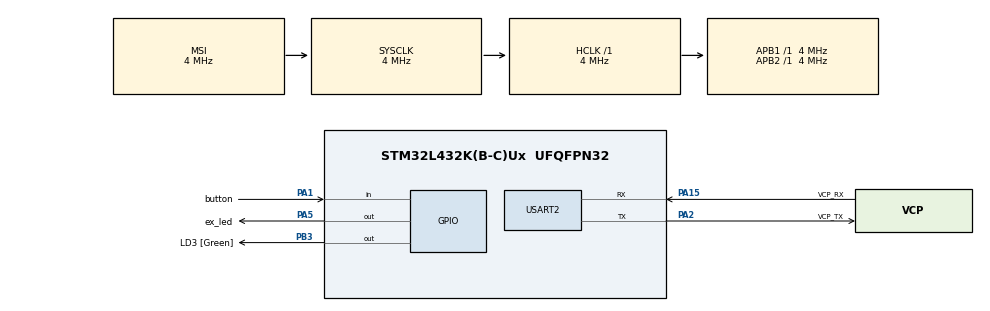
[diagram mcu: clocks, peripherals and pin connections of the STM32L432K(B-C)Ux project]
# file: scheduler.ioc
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Mcu.Family=STM32L4
Mcu.Name=STM32L432K(B-C)Ux
Mcu.Package=UFQFPN32
NVIC.PriorityGroup=NVIC_PRIORITYGROUP_4
NVIC.TIM1_UP_TIM16_IRQn=true\:0\:0\:false\:false\:true\:true\:true\:true
PA0.GPIO_Label=MCO [High speed clock in]
PA0.Mode=HSE-External-Clock-Source-for-LittleOrca
PA0.Signal=RCC_CK_IN
PA1.GPIO_Label=button
PA1.GPIO_PuPd=GPIO_PULLUP
PA1.Signal=GPIO_Input
PA13\ (JTMS-SWDIO).GPIO_Label=SWDIO
PA13\ (JTMS-SWDIO).Mode=Serial_Wire
PA13\ (JTMS-SWDIO).Signal=SYS_JTMS-SWDIO
PA14\ (JTCK-SWCLK).GPIO_Label=SWCLK
PA14\ (JTCK-SWCLK).Mode=Serial_Wire
PA14\ (JTCK-SWCLK).Signal=SYS_JTCK-SWCLK
PA15\ (JTDI).GPIO_Label=VCP_RX
PA15\ (JTDI).Mode=Asynchronous
PA15\ (JTDI).Signal=USART2_RX
PA2.GPIO_Label=VCP_TX
PA2.Mode=Asynchronous
PA2.Signal=USART2_TX
PA5.GPIO_Label=ex_led
PA5.Signal=GPIO_Output
PB3\ (JTDO-TRACESWO).GPIO_Label=LD3 [Green]
PB3\ (JTDO-TRACESWO).Signal=GPIO_Output
PC14-OSC32_IN\ (PC14).Mode=LSE-External-Oscillator
PC14-OSC32_IN\ (PC14).Signal=RCC_OSC32_IN
PC15-OSC32_OUT\ (PC15).Mode=LSE-External-Oscillator
PC15-OSC32_OUT\ (PC15).Signal=RCC_OSC32_OUT
ProjectManager.HeapSize=0x200
ProjectManager.StackSize=0x400
ProjectManager.TargetToolchain=STM32CubeIDE
RCC.AHBFreq_Value=4000000
RCC.APB1Freq_Value=4000000
RCC.APB1TimFreq_Value=4000000
RCC.APB2Freq_Value=4000000
RCC.APB2TimFreq_Value=4000000
RCC.CortexFreq_Value=4000000
RCC.HCLKFreq_Value=4000000
RCC.HSE_VALUE=8000000
RCC.HSI16_VALUE=16000000
RCC.HSI48_VALUE=48000000
RCC.HSI_VALUE=16000000
RCC.MSI_VALUE=4000000
RCC.PLLMUL=RCC_PLLMUL_4
RCC.PLLN=16
RCC.SYSCLKFreq_VALUE=4000000
RCC.VCOOutputFreq_Value=64000000
TIM1.Period=3
TIM1.Prescaler=999
USART2.VirtualMode-Asynchronous=VM_ASYNC
VP_TIM1_VS_ClockSourceINT.Mode=Internal
board=NUCLEO-L432KC

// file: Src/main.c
#include "main.h"
#include <string.h>
#include <stdarg.h>
#include <stdio.h>
#include <stdint.h>

void Button_Task(void);
extern UART_HandleTypeDef huart2;
volatile uint32_t msTicks = 0;

void UART_Print(const char *msg)
{
    HAL_UART_Transmit(&huart2, (uint8_t*)msg, strlen(msg), HAL_MAX_DELAY);
}

void UART_Printf(const char *fmt, ...)
{
    char buf[128];
    va_list args;
    va_start(args, fmt);
    vsnprintf(buf, sizeof(buf), fmt, args);
    va_end(args);
    HAL_UART_Transmit(&huart2, (uint8_t*)buf, strlen(buf), HAL_MAX_DELAY);
}

TIM_HandleTypeDef htim1;

UART_HandleTypeDef huart2;

/* USER CODE BEGIN PV */
uint16_t data[]={GPIO_PIN_5,0x0000};
static uint32_t lastL  = 0;
static uint32_t lastU = 0;
static uint32_t lastB = 0;

/* USER CODE END PV */

void SystemClock_Config(void);
static void MX_GPIO_Init(void);
static void MX_TIM1_Init(void);
static void MX_USART2_UART_Init(void);

/* USER CODE BEGIN 0 */
void HAL_TIM_PeriodElapsedCallback(TIM_HandleTypeDef *htim) {
    if (htim->Instance == TIM1) {  // or TIM1, TIM6, etc.
        msTicks++;  // count milliseconds
    }
}
/* USER CODE END 0 */

int main(void)
{

  /* MCU Configuration--------------------------------------------------------*/

  /* Reset of all peripherals, Initializes the Flash interface and the Systick. */
  HAL_Init();

  /* Configure the system clock */
  SystemClock_Config();

  /* Initialize all configured peripherals */
  MX_GPIO_Init();
  MX_TIM1_Init();
  MX_USART2_UART_Init();
  /* USER CODE BEGIN 2 */
   //__HAL_TIM_ENABLE_DMA(&htim1, TIM_DMA_UPDATE);
   //HAL_DMA_Start(&hdma_tim1_up,(uint32_t)data,(uint32_t)&GPIOA->ODR,2);
   HAL_TIM_Base_Start_IT(&htim1);
  /* USER CODE BEGIN 2 */

  /* USER CODE END 2 */

  /* Infinite loop */
  /* USER CODE BEGIN WHILE */
   while (1) {
       uint32_t now = msTicks;
       uint32_t ms = msTicks;             // snapshot
       uint32_t s  = ms / 1000;
       uint32_t ms_rem = ms % 1000;
       static uint32_t c = 0;
       static uint8_t led_on = 0;
       if ((now - lastL) >= 1500) {
    	   lastL = now;
    	   if (!led_on) {
    	           HAL_GPIO_WritePin(ex_led_GPIO_Port, ex_led_Pin, GPIO_PIN_SET);
    	           led_on = 1;
    	           c++;                // count only when turning on
    	       } else {
    	           HAL_GPIO_WritePin(ex_led_GPIO_Port, ex_led_Pin, GPIO_PIN_RESET);
    	           led_on = 0;
    	       }
       }
       if ((now - lastU) >= 3000) {
           UART_Printf("Total time elapsed in milliseconds: %lu milliseconds\r\n", msTicks);
           for(int i = 0; i < 1000; i++){
        	   int j = i/1000;
           }
           UART_Printf("Total time elapsed in: %lu.%09lu seconds\r\n", s, ms_rem);
          // UART_Printf("LED has flashed %lu times \r\n", c);
           lastU = now;
       }
       if ((now - lastB) >= 10) {
           Button_Task();
           lastB = now;
       }
   }
}

  /* USER CODE END 3 */

void Button_Task(void)
{
    static uint8_t  debouncedState    = 1;
    static uint8_t  lastRaw           = 1;
    static uint32_t lastChangeMs      = 0;
    static uint8_t  lastReportedState = 1;
    static uint32_t pressCount        = 0;

    uint8_t  raw = HAL_GPIO_ReadPin(button_GPIO_Port, button_Pin); // <— use CubeMX names
    uint32_t now = msTicks;                                        // <— same timebase

    if (raw != lastRaw) {
        lastRaw = raw;
        lastChangeMs = now;
    }

    if ((now - lastChangeMs) > 20 && raw != debouncedState) {
        debouncedState = raw;

        if (debouncedState == GPIO_PIN_RESET && lastReportedState == GPIO_PIN_SET) {
            pressCount++;
            HAL_GPIO_TogglePin(ex_led_GPIO_Port, ex_led_Pin);      // <— same LED
            UART_Printf("Button pressed! Count = %lu\r\n", pressCount);
        }
        lastReportedState = debouncedState;
    }
}

void SystemClock_Config(void)
{
  RCC_OscInitTypeDef RCC_OscInitStruct = {0};
  RCC_ClkInitTypeDef RCC_ClkInitStruct = {0};

  /** Configure the main internal regulator output voltage
  */
  if (HAL_PWREx_ControlVoltageScaling(PWR_REGULATOR_VOLTAGE_SCALE1) != HAL_OK)
  {
    Error_Handler();
  }

  /** Configure LSE Drive Capability
  */
  HAL_PWR_EnableBkUpAccess();
  __HAL_RCC_LSEDRIVE_CONFIG(RCC_LSEDRIVE_LOW);

  /** Initializes the RCC Oscillators according to the specified parameters
  * in the RCC_OscInitTypeDef structure.
  */
  RCC_OscInitStruct.OscillatorType = RCC_OSCILLATORTYPE_LSE|RCC_OSCILLATORTYPE_MSI;
  RCC_OscInitStruct.LSEState = RCC_LSE_ON;
  RCC_OscInitStruct.MSIState = RCC_MSI_ON;
  RCC_OscInitStruct.MSICalibrationValue = 0;
  RCC_OscInitStruct.MSIClockRange = RCC_MSIRANGE_6;
  RCC_OscInitStruct.PLL.PLLState = RCC_PLL_NONE;
  if (HAL_RCC_OscConfig(&RCC_OscInitStruct) != HAL_OK)
  {
    Error_Handler();
  }

  /** Initializes the CPU, AHB and APB buses clocks
  */
  RCC_ClkInitStruct.ClockType = RCC_CLOCKTYPE_HCLK|RCC_CLOCKTYPE_SYSCLK
                              |RCC_CLOCKTYPE_PCLK1|RCC_CLOCKTYPE_PCLK2;
  RCC_ClkInitStruct.SYSCLKSource = RCC_SYSCLKSOURCE_MSI;
  RCC_ClkInitStruct.AHBCLKDivider = RCC_SYSCLK_DIV1;
  RCC_ClkInitStruct.APB1CLKDivider = RCC_HCLK_DIV1;
  RCC_ClkInitStruct.APB2CLKDivider = RCC_HCLK_DIV1;

  if (HAL_RCC_ClockConfig(&RCC_ClkInitStruct, FLASH_LATENCY_0) != HAL_OK)
  {
    Error_Handler();
  }

  /** Enable MSI Auto calibration
  */
  HAL_RCCEx_EnableMSIPLLMode();
}

static void MX_TIM1_Init(void)
{

  TIM_ClockConfigTypeDef sClockSourceConfig = {0};
  TIM_MasterConfigTypeDef sMasterConfig = {0};

  htim1.Instance = TIM1;
  htim1.Init.Prescaler = 999;
  htim1.Init.CounterMode = TIM_COUNTERMODE_UP;
  htim1.Init.Period = 3;
  htim1.Init.ClockDivision = TIM_CLOCKDIVISION_DIV1;
  htim1.Init.RepetitionCounter = 0;
  htim1.Init.AutoReloadPreload = TIM_AUTORELOAD_PRELOAD_DISABLE;
  if (HAL_TIM_Base_Init(&htim1) != HAL_OK)
  {
    Error_Handler();
  }
  sClockSourceConfig.ClockSource = TIM_CLOCKSOURCE_INTERNAL;
  if (HAL_TIM_ConfigClockSource(&htim1, &sClockSourceConfig) != HAL_OK)
  {
    Error_Handler();
  }
  sMasterConfig.MasterOutputTrigger = TIM_TRGO_RESET;
  sMasterConfig.MasterOutputTrigger2 = TIM_TRGO2_RESET;
  sMasterConfig.MasterSlaveMode = TIM_MASTERSLAVEMODE_DISABLE;
  if (HAL_TIMEx_MasterConfigSynchronization(&htim1, &sMasterConfig) != HAL_OK)
  {
    Error_Handler();
  }

}

static void MX_USART2_UART_Init(void)
{

  huart2.Instance = USART2;
  huart2.Init.BaudRate = 115200;
  huart2.Init.WordLength = UART_WORDLENGTH_8B;
  huart2.Init.StopBits = UART_STOPBITS_1;
  huart2.Init.Parity = UART_PARITY_NONE;
  huart2.Init.Mode = UART_MODE_TX_RX;
  huart2.Init.HwFlowCtl = UART_HWCONTROL_NONE;
  huart2.Init.OverSampling = UART_OVERSAMPLING_16;
  huart2.Init.OneBitSampling = UART_ONE_BIT_SAMPLE_DISABLE;
  huart2.AdvancedInit.AdvFeatureInit = UART_ADVFEATURE_NO_INIT;
  if (HAL_UART_Init(&huart2) != HAL_OK)
  {
    Error_Handler();
  }

}

static void MX_GPIO_Init(void)
{
  GPIO_InitTypeDef GPIO_InitStruct = {0};

  /* GPIO Ports Clock Enable */
  __HAL_RCC_GPIOC_CLK_ENABLE();
  __HAL_RCC_GPIOA_CLK_ENABLE();
  __HAL_RCC_GPIOB_CLK_ENABLE();

  /*Configure GPIO pin Output Level */
  HAL_GPIO_WritePin(ex_led_GPIO_Port, ex_led_Pin, GPIO_PIN_RESET);

  /*Configure GPIO pin Output Level */
  HAL_GPIO_WritePin(LD3_GPIO_Port, LD3_Pin, GPIO_PIN_RESET);

  /*Configure GPIO pin : button_Pin */
  GPIO_InitStruct.Pin = button_Pin;
  GPIO_InitStruct.Mode = GPIO_MODE_INPUT;
  GPIO_InitStruct.Pull = GPIO_PULLUP;
  HAL_GPIO_Init(button_GPIO_Port, &GPIO_InitStruct);

  /*Configure GPIO pin : ex_led_Pin */
  GPIO_InitStruct.Pin = ex_led_Pin;
  GPIO_InitStruct.Mode = GPIO_MODE_OUTPUT_PP;
  GPIO_InitStruct.Pull = GPIO_NOPULL;
  GPIO_InitStruct.Speed = GPIO_SPEED_FREQ_LOW;
  HAL_GPIO_Init(ex_led_GPIO_Port, &GPIO_InitStruct);

  /*Configure GPIO pin : LD3_Pin */
  GPIO_InitStruct.Pin = LD3_Pin;
  GPIO_InitStruct.Mode = GPIO_MODE_OUTPUT_PP;
  GPIO_InitStruct.Pull = GPIO_NOPULL;
  GPIO_InitStruct.Speed = GPIO_SPEED_FREQ_LOW;
  HAL_GPIO_Init(LD3_GPIO_Port, &GPIO_InitStruct);

}

void Error_Handler(void)
{
  __disable_irq();
  while (1)
  {
  }
}
